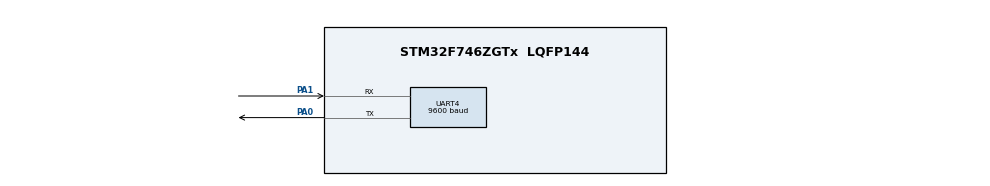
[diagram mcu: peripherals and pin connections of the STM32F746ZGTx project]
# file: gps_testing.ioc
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CORTEX_M7.default_mode_Activation=1
Dma.Request0=UART4_RX
Dma.UART4_RX.0.Direction=DMA_PERIPH_TO_MEMORY
Dma.UART4_RX.0.FIFOMode=DMA_FIFOMODE_DISABLE
Dma.UART4_RX.0.Instance=DMA1_Stream2
Dma.UART4_RX.0.MemDataAlignment=DMA_MDATAALIGN_BYTE
Dma.UART4_RX.0.MemInc=DMA_MINC_ENABLE
Dma.UART4_RX.0.Mode=DMA_CIRCULAR
Dma.UART4_RX.0.PeriphDataAlignment=DMA_PDATAALIGN_BYTE
Dma.UART4_RX.0.PeriphInc=DMA_PINC_DISABLE
Dma.UART4_RX.0.Priority=DMA_PRIORITY_LOW
Mcu.Family=STM32F7
Mcu.Name=STM32F746ZGTx
Mcu.Package=LQFP144
NVIC.DMA1_Stream2_IRQn=true\:0\:0\:false\:false\:true\:false\:true\:true
NVIC.PriorityGroup=NVIC_PRIORITYGROUP_4
PA0/WKUP.Mode=Asynchronous
PA0/WKUP.Signal=UART4_TX
PA1.Mode=Asynchronous
PA1.Signal=UART4_RX
PH0/OSC_IN.Mode=HSE-External-Oscillator
PH0/OSC_IN.Signal=RCC_OSC_IN
PH1/OSC_OUT.Mode=HSE-External-Oscillator
PH1/OSC_OUT.Signal=RCC_OSC_OUT
ProjectManager.HeapSize=0x200
ProjectManager.StackSize=0x400
ProjectManager.TargetToolchain=STM32CubeIDE
RCC.HSE_VALUE=25000000
RCC.HSI_VALUE=16000000
RCC.LSE_VALUE=32768
RCC.USBFreq_Value=96000000
RCC.VCOOutputFreq_Value=192000000
UART4.BaudRate=9600
board=custom

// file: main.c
/* USER CODE BEGIN Header */
/**
  ******************************************************************************
  * @file           : main.c
  * @brief          : Main program body
  ******************************************************************************
  * @attention
  *
  * Copyright (c) 2024 STMicroelectronics.
  * All rights reserved.
  *
  * This software is licensed under terms that can be found in the LICENSE file
  * in the root directory of this software component.
  * If no LICENSE file comes with this software, it is provided AS-IS.
  *
  ******************************************************************************
  */
/* USER CODE END Header */
#include "main.h"
#include "stdio.h"

UART_HandleTypeDef huart4;
DMA_HandleTypeDef hdma_uart4_rx;

/* USER CODE BEGIN PV */
#define GPSBUFSIZE 128
UART_HandleTypeDef huart4;
uint8_t rx_data = 0;
uint8_t rx_buffer[GPSBUFSIZE];
uint8_t rx_index = 0;
/* USER CODE END PV */

void SystemClock_Config(void);
static void MPU_Config(void);
static void MX_GPIO_Init(void);
static void MX_DMA_Init(void);
static void MX_UART4_Init(void);
void GPS_UART_CallBack();
int GPS_UART_Validate(char *nmeastr);
void GPS_parse(char *GPSstrParse);
float GPS_nmea_to_dec(float deg_coord, char nsew);

typedef struct{

    // calculated values
    float dec_longitude;
    float dec_latitude;
    float altitude_ft;

    // GGA - Global Positioning System Fixed Data
    float nmea_longitude;
    float nmea_latitude;
    float utc_time;
    char ns, ew;
    int lock;
    int satelites;
    float hdop;
    float msl_altitude;
    char msl_units;

    // RMC - Recommended Minimmum Specific GNS Data
    char rmc_status;
    float speed_k;
    float course_d;
    int date;

    // GLL
    char gll_status;

    // VTG - Course over ground, ground speed
    float course_t; // ground speed true
    char course_t_unit;
    float course_m; // magnetic
    char course_m_unit;
    char speed_k_unit;
    float speed_km; // speek km/hr
    char speed_km_unit;
} GPS_t;

GPS_t GPS;

void GPS_UART_CallBack()
{
	printf("GPS_UART_CallBack function is called.\n");
	printf("rx_data: %s", rx_buffer);
//	printf("No data");
		if (rx_data != '\n' && rx_index <sizeof(rx_buffer))
		{
			rx_buffer[rx_index++]=rx_data;
	/*		if ((rx_buffer)==0)
			{
				printf("No data");
			}
			else
			{

			}
	*/
			printf("GPS data received : %s\n",rx_buffer[rx_index++]);
		    if (rx_index > 128)
		    {
		    	if (GPS_UART_Validate((char*) rx_buffer))
		    	GPS_parse((char*) rx_buffer);

		        rx_index=0;
		    }
		    else
		    {
		    	printf("Not Valid.");
		    }
		}
		else
		{
			printf("ERROR!!! Data is not being fetched.");
		}

	//GPS_UART_Validate();
	}
int GPS_UART_Validate(char *nmeastr)
{
    printf("This function is called by the GPS_UART_CallBack: GPS_UART_Validate function is called.\n");
    char check[3];
        char checkcalcstr[3];
        int i;
        int calculated_check;

        i=0;
        calculated_check=0;

    	if (nmeastr[i]='$')
    	{
    		i++;
    	}
    	else
    	{
    		return 0;
    	}

    	while((nmeastr[i] !=0) && (nmeastr[i] != '*')&& (i<75))
    	{
    		calculated_check ^= nmeastr[i];  //calculate checksum
    		i++;
    	}

    	if(i >= 75)
    	{
    		printf("i greater than 75");
    		return 0;// the string was too long so return an error
    	}
    	else
    	{

    	}
    	if (nmeastr[i] == '*')
    	{
    	        check[0] = nmeastr[i+1];    //put hex chars in check string
    	        check[1] = nmeastr[i+2];
    	        check[2] = 0;
    	}
    	else
    	{
    	   return 0;// no checksum separator found there for invalid
    	}
    	   sprintf(checkcalcstr,"%02X",calculated_check);
    	   return((checkcalcstr[0] == check[0]) && (checkcalcstr[1] == check[1])) ? 1 : 0 ;

//    GPS_parse();
}

void GPS_parse(char *GPSstrParse)
{
   printf("This function is called by the GPS_UART_Validate: GPS_parse function is called.\n");
   if(!strncmp(GPSstrParse, "$GPGGA", 6)){
      	if (sscanf(GPSstrParse, "$GPGGA,%f,%f,%c,%f,%c,%d,%d,%f,%f,%c", &GPS.utc_time, &GPS.nmea_latitude, &GPS.ns, &GPS.nmea_longitude, &GPS.ew, &GPS.lock, &GPS.satelites, &GPS.hdop, &GPS.msl_altitude, &GPS.msl_units) >= 1){
      		GPS.dec_latitude = GPS_nmea_to_dec(GPS.nmea_latitude, GPS.ns);
      		GPS.dec_longitude = GPS_nmea_to_dec(GPS.nmea_longitude, GPS.ew);
      		return;
      	}
      }
      else if (!strncmp(GPSstrParse, "$GPRMC", 6)){
      	if(sscanf(GPSstrParse, "$GPRMC,%f,%f,%c,%f,%c,%f,%f,%d", &GPS.utc_time, &GPS.nmea_latitude, &GPS.ns, &GPS.nmea_longitude, &GPS.ew, &GPS.speed_k, &GPS.course_d, &GPS.date) >= 1)
      		return;

      }
      else if (!strncmp(GPSstrParse, "$GPGLL", 6)){
          if(sscanf(GPSstrParse, "$GPGLL,%f,%c,%f,%c,%f,%c", &GPS.nmea_latitude, &GPS.ns, &GPS.nmea_longitude, &GPS.ew, &GPS.utc_time, &GPS.gll_status) >= 1)
              return;
      }
      else if (!strncmp(GPSstrParse, "$GPVTG", 6)){
          if(sscanf(GPSstrParse, "$GPVTG,%f,%c,%f,%c,%f,%c,%f,%c", &GPS.course_t, &GPS.course_t_unit, &GPS.course_m, &GPS.course_m_unit, &GPS.speed_k, &GPS.speed_k_unit, &GPS.speed_km, &GPS.speed_km_unit) >= 1)
              return;
      }

   //GPS_nmea_to_dec();

}
float GPS_nmea_to_dec(float deg_coord, char nsew) {
    printf("This function is called by the GPS_parse: GPS_nmea_to_dec function is called.\n");
    printf("____________________________________________\n");
    int degree = (int)(deg_coord/100);
        float minutes = deg_coord - degree*100;
        float dec_deg = minutes / 60;
        float decimal = degree + dec_deg;
        if (nsew == 'S' || nsew == 'W') { // return negative
            decimal *= -1;
        }
        return decimal;
}

int _write(int file, char *ptr, int len)
{
  int DataIdx;

  for (DataIdx = 0; DataIdx < len; DataIdx++)
  {
    ITM_SendChar(*ptr++);
  }
  return len;
}

int main(void)
{

  /* MPU Configuration--------------------------------------------------------*/
  MPU_Config();

  /* MCU Configuration--------------------------------------------------------*/

  /* Reset of all peripherals, Initializes the Flash interface and the Systick. */
  HAL_Init();

  /* Configure the system clock */
  SystemClock_Config();

  /* Initialize all configured peripherals */
  MX_GPIO_Init();
  MX_DMA_Init();
  MX_UART4_Init();

  /* Infinite loop */
  while (1)
  {
	  HAL_UART_Receive(&huart4, &rx_data ,11,100);
	  printf(rx_data);
	  //printf( " While loop execution.\n ");
	  GPS_UART_CallBack();
  }
}

void SystemClock_Config(void)
{
  RCC_OscInitTypeDef RCC_OscInitStruct = {0};
  RCC_ClkInitTypeDef RCC_ClkInitStruct = {0};

  /** Configure the main internal regulator output voltage
  */
  __HAL_RCC_PWR_CLK_ENABLE();
  __HAL_PWR_VOLTAGESCALING_CONFIG(PWR_REGULATOR_VOLTAGE_SCALE3);

  /** Initializes the RCC Oscillators according to the specified parameters
  * in the RCC_OscInitTypeDef structure.
  */
  RCC_OscInitStruct.OscillatorType = RCC_OSCILLATORTYPE_HSI;
  RCC_OscInitStruct.HSIState = RCC_HSI_ON;
  RCC_OscInitStruct.HSICalibrationValue = RCC_HSICALIBRATION_DEFAULT;
  RCC_OscInitStruct.PLL.PLLState = RCC_PLL_NONE;
  if (HAL_RCC_OscConfig(&RCC_OscInitStruct) != HAL_OK)
  {
    Error_Handler();
  }

  /** Initializes the CPU, AHB and APB buses clocks
  */
  RCC_ClkInitStruct.ClockType = RCC_CLOCKTYPE_HCLK|RCC_CLOCKTYPE_SYSCLK
                              |RCC_CLOCKTYPE_PCLK1|RCC_CLOCKTYPE_PCLK2;
  RCC_ClkInitStruct.SYSCLKSource = RCC_SYSCLKSOURCE_HSI;
  RCC_ClkInitStruct.AHBCLKDivider = RCC_SYSCLK_DIV1;
  RCC_ClkInitStruct.APB1CLKDivider = RCC_HCLK_DIV1;
  RCC_ClkInitStruct.APB2CLKDivider = RCC_HCLK_DIV1;

  if (HAL_RCC_ClockConfig(&RCC_ClkInitStruct, FLASH_LATENCY_0) != HAL_OK)
  {
    Error_Handler();
  }
}

static void MX_UART4_Init(void)
{

  huart4.Instance = UART4;
  huart4.Init.BaudRate = 9600;
  huart4.Init.WordLength = UART_WORDLENGTH_8B;
  huart4.Init.StopBits = UART_STOPBITS_1;
  huart4.Init.Parity = UART_PARITY_NONE;
  huart4.Init.Mode = UART_MODE_TX_RX;
  huart4.Init.HwFlowCtl = UART_HWCONTROL_NONE;
  huart4.Init.OverSampling = UART_OVERSAMPLING_16;
  huart4.Init.OneBitSampling = UART_ONE_BIT_SAMPLE_DISABLE;
  huart4.AdvancedInit.AdvFeatureInit = UART_ADVFEATURE_NO_INIT;
  if (HAL_UART_Init(&huart4) != HAL_OK)
  {
    Error_Handler();
  }
  /* USER CODE BEGIN UART4_Init 2 */
  HAL_UART_Receive(&huart4, &rx_data ,128,100);
  /* USER CODE END UART4_Init 2 */

}

static void MX_DMA_Init(void)
{

  /* DMA controller clock enable */
  __HAL_RCC_DMA1_CLK_ENABLE();

  /* DMA interrupt init */
  /* DMA1_Stream2_IRQn interrupt configuration */
  HAL_NVIC_SetPriority(DMA1_Stream2_IRQn, 0, 0);
  HAL_NVIC_EnableIRQ(DMA1_Stream2_IRQn);

}

static void MX_GPIO_Init(void)
{

  /* GPIO Ports Clock Enable */
  __HAL_RCC_GPIOH_CLK_ENABLE();
  __HAL_RCC_GPIOA_CLK_ENABLE();

}

 /* MPU Configuration */

void MPU_Config(void)
{
  MPU_Region_InitTypeDef MPU_InitStruct = {0};

  /* Disables the MPU */
  HAL_MPU_Disable();

  /** Initializes and configures the Region and the memory to be protected
  */
  MPU_InitStruct.Enable = MPU_REGION_ENABLE;
  MPU_InitStruct.Number = MPU_REGION_NUMBER0;
  MPU_InitStruct.BaseAddress = 0x0;
  MPU_InitStruct.Size = MPU_REGION_SIZE_4GB;
  MPU_InitStruct.SubRegionDisable = 0x87;
  MPU_InitStruct.TypeExtField = MPU_TEX_LEVEL0;
  MPU_InitStruct.AccessPermission = MPU_REGION_NO_ACCESS;
  MPU_InitStruct.DisableExec = MPU_INSTRUCTION_ACCESS_DISABLE;
  MPU_InitStruct.IsShareable = MPU_ACCESS_SHAREABLE;
  MPU_InitStruct.IsCacheable = MPU_ACCESS_NOT_CACHEABLE;
  MPU_InitStruct.IsBufferable = MPU_ACCESS_NOT_BUFFERABLE;

  HAL_MPU_ConfigRegion(&MPU_InitStruct);
  /* Enables the MPU */
  HAL_MPU_Enable(MPU_PRIVILEGED_DEFAULT);

}

void Error_Handler(void)
{
  __disable_irq();
  while (1)
  {
  }
}
